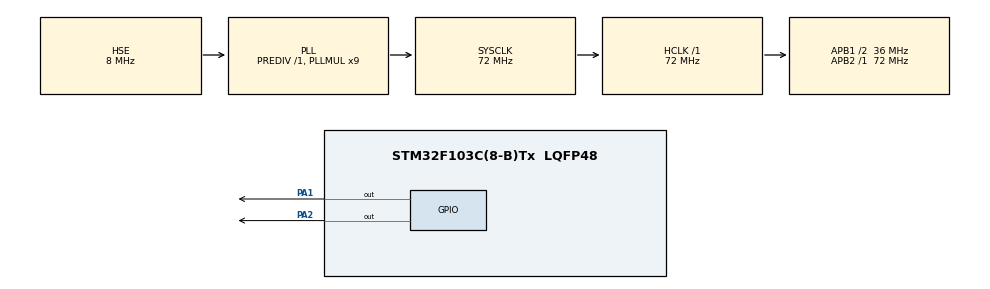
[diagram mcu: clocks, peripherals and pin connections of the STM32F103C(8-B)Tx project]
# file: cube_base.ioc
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Mcu.Family=STM32F1
Mcu.Name=STM32F103C(8-B)Tx
Mcu.Package=LQFP48
NVIC.PriorityGroup=NVIC_PRIORITYGROUP_4
PA1.GPIO_ModeDefaultOutputPP=GPIO_MODE_OUTPUT_OD
PA1.GPIO_PuPd=GPIO_PULLUP
PA1.PinState=GPIO_PIN_SET
PA1.Signal=GPIO_Output
PA2.GPIO_ModeDefaultOutputPP=GPIO_MODE_OUTPUT_OD
PA2.GPIO_PuPd=GPIO_PULLUP
PA2.PinState=GPIO_PIN_SET
PA2.Signal=GPIO_Output
PD0-OSC_IN.Mode=HSE-External-Oscillator
PD0-OSC_IN.Signal=RCC_OSC_IN
PD1-OSC_OUT.Mode=HSE-External-Oscillator
PD1-OSC_OUT.Signal=RCC_OSC_OUT
ProjectManager.HeapSize=0x200
ProjectManager.StackSize=0x400
ProjectManager.TargetToolchain=Makefile
RCC.AHBFreq_Value=72000000
RCC.APB1CLKDivider=RCC_HCLK_DIV2
RCC.APB1Freq_Value=36000000
RCC.APB1TimFreq_Value=72000000
RCC.APB2Freq_Value=72000000
RCC.APB2TimFreq_Value=72000000
RCC.HCLKFreq_Value=72000000
RCC.PLLMUL=RCC_PLL_MUL9
RCC.PLLSourceVirtual=RCC_PLLSOURCE_HSE
RCC.SYSCLKFreq_VALUE=72000000
RCC.SYSCLKSource=RCC_SYSCLKSOURCE_PLLCLK
RCC.USBFreq_Value=72000000
VP_SYS_VS_ND.Mode=No_Debug
board=custom

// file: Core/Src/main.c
/* USER CODE BEGIN Header */
/**
  ******************************************************************************
  * @file           : main.c
  * @brief          : Main program body
  ******************************************************************************
  * @attention
  *
  * Copyright (c) 2024 STMicroelectronics.
  * All rights reserved.
  *
  * This software is licensed under terms that can be found in the LICENSE file
  * in the root directory of this software component.
  * If no LICENSE file comes with this software, it is provided AS-IS.
  *
  ******************************************************************************
  */
/* USER CODE END Header */
#include "main.h"

/* USER CODE BEGIN Includes */
#include "ucos_ii.h"
/* USER CODE END Includes */

/* USER CODE BEGIN PM */
#define COMMON_STK_SIZE 256
/* USER CODE END PM */

void SystemClock_Config(void);
static void MX_GPIO_Init(void);
/* USER CODE BEGIN PFP */
void init_task(void *ppdata);
void led_task(void *ppdata);
void button_task(void *ppdata);
/* USER CODE END PFP */

/* USER CODE BEGIN 0 */
OS_STK init_task_stk[COMMON_STK_SIZE];
OS_STK led_task_stk[COMMON_STK_SIZE];
/* USER CODE END 0 */

int main(void)
{

  /* USER CODE BEGIN 1 */
  OSInit();
  OSTaskCreate(init_task,NULL,&init_task_stk[COMMON_STK_SIZE-1],5);
  OSStart();
  /* USER CODE END 1 */

  /* MCU Configuration--------------------------------------------------------*/

  /* Reset of all peripherals, Initializes the Flash interface and the Systick. */
  HAL_Init();

  /* Configure the system clock */
  SystemClock_Config();

  /* Initialize all configured peripherals */
  MX_GPIO_Init();

  /* Infinite loop */
  while (1)
  {

  }
}

void SystemClock_Config(void)
{
  RCC_OscInitTypeDef RCC_OscInitStruct = {0};
  RCC_ClkInitTypeDef RCC_ClkInitStruct = {0};

  /** Initializes the RCC Oscillators according to the specified parameters
  * in the RCC_OscInitTypeDef structure.
  */
  RCC_OscInitStruct.OscillatorType = RCC_OSCILLATORTYPE_HSE;
  RCC_OscInitStruct.HSEState = RCC_HSE_ON;
  RCC_OscInitStruct.HSEPredivValue = RCC_HSE_PREDIV_DIV1;
  RCC_OscInitStruct.HSIState = RCC_HSI_ON;
  RCC_OscInitStruct.PLL.PLLState = RCC_PLL_ON;
  RCC_OscInitStruct.PLL.PLLSource = RCC_PLLSOURCE_HSE;
  RCC_OscInitStruct.PLL.PLLMUL = RCC_PLL_MUL9;
  if (HAL_RCC_OscConfig(&RCC_OscInitStruct) != HAL_OK)
  {
    Error_Handler();
  }

  /** Initializes the CPU, AHB and APB buses clocks
  */
  RCC_ClkInitStruct.ClockType = RCC_CLOCKTYPE_HCLK|RCC_CLOCKTYPE_SYSCLK
                              |RCC_CLOCKTYPE_PCLK1|RCC_CLOCKTYPE_PCLK2;
  RCC_ClkInitStruct.SYSCLKSource = RCC_SYSCLKSOURCE_PLLCLK;
  RCC_ClkInitStruct.AHBCLKDivider = RCC_SYSCLK_DIV1;
  RCC_ClkInitStruct.APB1CLKDivider = RCC_HCLK_DIV2;
  RCC_ClkInitStruct.APB2CLKDivider = RCC_HCLK_DIV1;

  if (HAL_RCC_ClockConfig(&RCC_ClkInitStruct, FLASH_LATENCY_2) != HAL_OK)
  {
    Error_Handler();
  }
}

static void MX_GPIO_Init(void)
{
  GPIO_InitTypeDef GPIO_InitStruct = {0};

  /* GPIO Ports Clock Enable */
  __HAL_RCC_GPIOD_CLK_ENABLE();
  __HAL_RCC_GPIOA_CLK_ENABLE();

  /*Configure GPIO pin Output Level */
  HAL_GPIO_WritePin(GPIOA, GPIO_PIN_1|GPIO_PIN_2, GPIO_PIN_SET);

  /*Configure GPIO pins : PA1 PA2 */
  GPIO_InitStruct.Pin = GPIO_PIN_1|GPIO_PIN_2;
  GPIO_InitStruct.Mode = GPIO_MODE_OUTPUT_OD;
  GPIO_InitStruct.Pull = GPIO_PULLUP;
  GPIO_InitStruct.Speed = GPIO_SPEED_FREQ_LOW;
  HAL_GPIO_Init(GPIOA, &GPIO_InitStruct);

}

/* USER CODE BEGIN 4 */
void init_task(void *ppdata)
{

  // MX_TIM2_Init();
  // MX_SPI1_Init();
  // HAL_TIM_Base_Start_IT(&htim2);
  // printf("%s\n\r",__FUNCTION__);
  HAL_Init();
  SystemClock_Config();
  MX_GPIO_Init();

  OSTaskCreate(led_task,NULL,&led_task_stk[COMMON_STK_SIZE-1],6);
  // OSTaskCreate(&button_task,NULL,button_task_stk,7);
  OSTaskDel(OS_PRIO_SELF);
}

void led_task(void *ppdata)
{

    // printf("%s\n\r",__FUNCTION__);
    for(;;)
    {
      HAL_GPIO_TogglePin(GPIOA,GPIO_PIN_1);
      OSTimeDly(20);
    }
}

void button_task(void *ppdata)
{
    for(;;)
    {
        if(GPIO_PIN_RESET == HAL_GPIO_ReadPin(GPIOA,GPIO_PIN_2))
        {
            OSTimeDly(20);
            if(GPIO_PIN_RESET == HAL_GPIO_ReadPin(GPIOA,GPIO_PIN_2))
            {
              // printf("%s\n\r",__FUNCTION__);
            }
        }
    }
}
/* USER CODE END 4 */

void Error_Handler(void)
{
  __disable_irq();
  while (1)
  {
  }
}
